VERSION "HIPBNYYYYYYYYYYYYYYYYYYYYYYYYYYYYYYYYYYYYY/4/%%%/4/'%**4YYY///"

NS_ :

BS_:

BU_: DBG VCU BMS MCM DCU DAQ S2C

BO_ 2023 Reserved1: 8 Vector__XXX

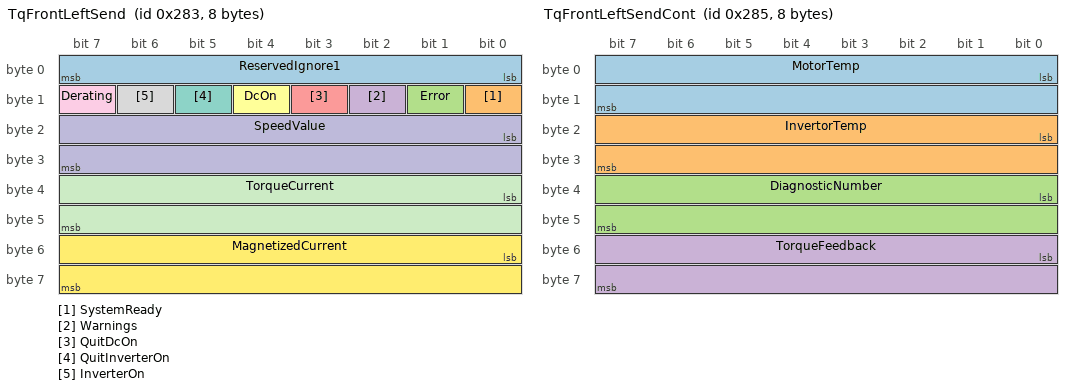
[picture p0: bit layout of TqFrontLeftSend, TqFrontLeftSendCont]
BO_ 643 TqFrontLeftSend: 8 Vector__XXX
 SG_ ReservedIgnore1 : 0|8@1+ (1,0) [0|1] "StatusWord" Vector__XXX
 SG_ SystemReady : 8|1@1+ (1,0) [0|1] "SystemReadySBM" Vector__XXX
 SG_ Error : 9|1@1+ (1,0) [0|1] "" Vector__XXX
 SG_ Warnings : 10|1@1+ (1,0) [0|1] "" Vector__XXX
 SG_ QuitDcOn : 11|1@1+ (1,0) [0|1] "HVActivation" Vector__XXX
 SG_ DcOn : 12|1@1+ (1,0) [0|1] "HVActivationLevel" Vector__XXX
 SG_ QuitInverterOn : 13|1@1+ (1,0) [0|1] "ControllerEnable" Vector__XXX
 SG_ InverterOn : 14|1@1+ (1,0) [0|1] "ControllerEnableAcknow" Vector__XXX
 SG_ Derating : 15|1@1+ (1,0) [0|1] "Nm" Vector__XXX
 SG_ SpeedValue : 16|16@1- (0.01,0) [0|5000] "1/rpm" Vector__XXX
 SG_ TorqueCurrent : 32|16@1- (0.01,0) [0|5000] "Iq" Vector__XXX
 SG_ MagnetizedCurrent : 48|16@1- (0.01,0) [0|5000] "Id" Vector__XXX

BO_ 645 TqFrontLeftSendCont: 8 Vector__XXX
 SG_ MotorTemp : 0|16@1- (0.1,0) [0|500] "C" Vector__XXX
 SG_ InvertorTemp : 16|16@1- (0.1,0) [0|500] "C" Vector__XXX
 SG_ DiagnosticNumber : 32|16@1+ (1,0) [0|20] "" Vector__XXX
 SG_ TorqueFeedback : 48|16@1- (0.1,0) [-30|30] "Nm" Vector__XXX

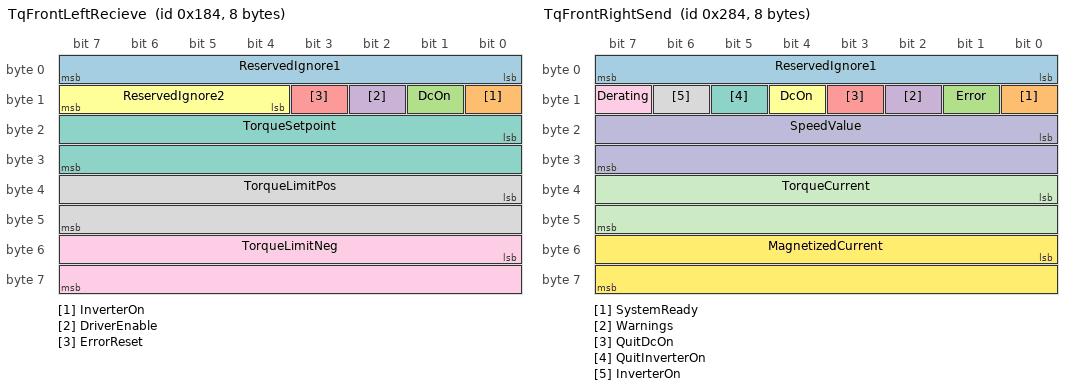
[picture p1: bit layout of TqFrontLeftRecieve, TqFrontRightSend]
BO_ 388 TqFrontLeftRecieve: 8 Vector__XXX
 SG_ ReservedIgnore1 : 0|8@1+ (1,0) [0|1] "" Vector__XXX
 SG_ InverterOn : 8|1@1+ (1,0) [0|1] "" Vector__XXX
 SG_ DcOn : 9|1@1+ (1,0) [0|1] "" Vector__XXX
 SG_ DriverEnable : 10|1@1+ (1,0) [0|1] "" Vector__XXX
 SG_ ErrorReset : 11|1@1+ (1,0) [0|1] "" Vector__XXX
 SG_ ReservedIgnore2 : 12|4@1+ (1,0) [0|1] "" Vector__XXX
 SG_ TorqueSetpoint : 16|16@1- (0.01,0) [-2.14|2.14] "%Nm" Vector__XXX
 SG_ TorqueLimitPos : 32|16@1- (0.1,0) [0|21] "Nm" Vector__XXX
 SG_ TorqueLimitNeg : 48|16@1- (0.1,0) [-21|0] "Nm" Vector__XXX

BO_ 644 TqFrontRightSend: 8 Vector__XXX
 SG_ ReservedIgnore1 : 0|8@1+ (1,0) [0|1] "StatusWord" Vector__XXX
 SG_ SystemReady : 8|1@1+ (1,0) [0|1] "SystemReadySBM" Vector__XXX
 SG_ Error : 9|1@1+ (1,0) [0|1] "" Vector__XXX
 SG_ Warnings : 10|1@1+ (1,0) [0|1] "" Vector__XXX
 SG_ QuitDcOn : 11|1@1+ (1,0) [0|1] "HVActivation" Vector__XXX
 SG_ DcOn : 12|1@1+ (1,0) [0|1] "HVActivationLevel" Vector__XXX
 SG_ QuitInverterOn : 13|1@1+ (1,0) [0|1] "ControllerEnable" Vector__XXX
 SG_ InverterOn : 14|1@1+ (1,0) [0|1] "ControllerEnableAcknow" Vector__XXX
 SG_ Derating : 15|1@1+ (1,0) [0|1] "Nm" Vector__XXX
 SG_ SpeedValue : 16|16@1- (0.01,0) [0|5000] "1/rpm" Vector__XXX
 SG_ TorqueCurrent : 32|16@1- (0.01,0) [0|5000] "Iq" Vector__XXX
 SG_ MagnetizedCurrent : 48|16@1- (0.01,0) [0|5000] "Id" Vector__XXX

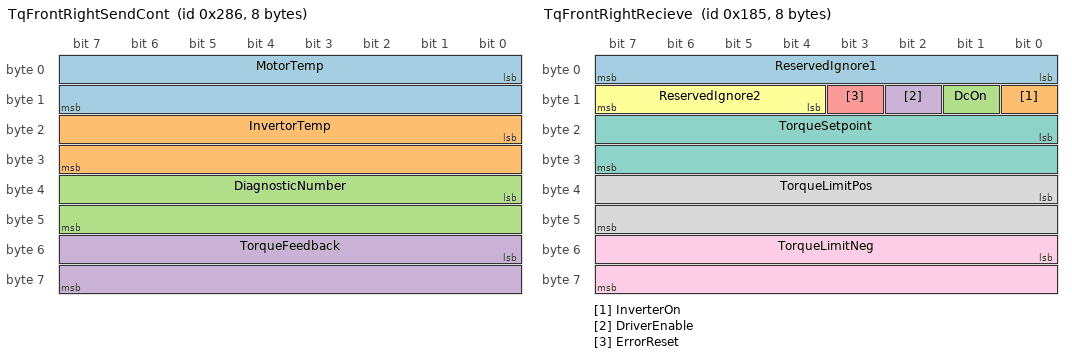
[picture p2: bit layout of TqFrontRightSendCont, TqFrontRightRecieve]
BO_ 646 TqFrontRightSendCont: 8 Vector__XXX
 SG_ MotorTemp : 0|16@1- (0.1,0) [0|500] "C" Vector__XXX
 SG_ InvertorTemp : 16|16@1- (0.1,0) [0|500] "C" Vector__XXX
 SG_ DiagnosticNumber : 32|16@1+ (1,0) [0|20] "" Vector__XXX
 SG_ TorqueFeedback : 48|16@1- (0.1,0) [-30|30] "Nm" Vector__XXX

BO_ 389 TqFrontRightRecieve: 8 Vector__XXX
 SG_ ReservedIgnore1 : 0|8@1+ (1,0) [0|1] "" Vector__XXX
 SG_ InverterOn : 8|1@1+ (1,0) [0|1] "" Vector__XXX
 SG_ DcOn : 9|1@1+ (1,0) [0|1] "" Vector__XXX
 SG_ DriverEnable : 10|1@1+ (1,0) [0|1] "" Vector__XXX
 SG_ ErrorReset : 11|1@1+ (1,0) [0|1] "" Vector__XXX
 SG_ ReservedIgnore2 : 12|4@1+ (1,0) [0|1] "" Vector__XXX
 SG_ TorqueSetpoint : 16|16@1- (0.01,0) [-2.14|2.14] "%Nm" Vector__XXX
 SG_ TorqueLimitPos : 32|16@1- (0.1,0) [0|21] "Nm" Vector__XXX
 SG_ TorqueLimitNeg : 48|16@1- (0.1,0) [-21|0] "Nm" Vector__XXX

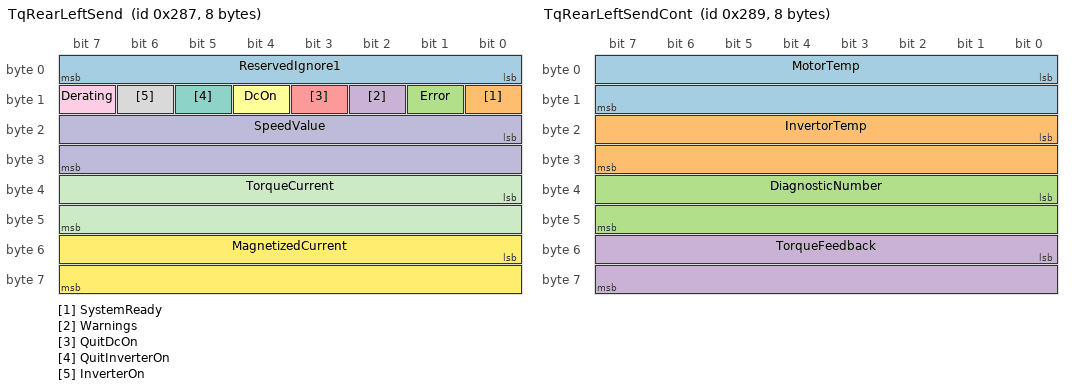
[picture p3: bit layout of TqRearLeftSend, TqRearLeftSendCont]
BO_ 647 TqRearLeftSend: 8 Vector__XXX
 SG_ ReservedIgnore1 : 0|8@1+ (1,0) [0|1] "StatusWord" Vector__XXX
 SG_ SystemReady : 8|1@1+ (1,0) [0|1] "SystemReadySBM" Vector__XXX
 SG_ Error : 9|1@1+ (1,0) [0|1] "" Vector__XXX
 SG_ Warnings : 10|1@1+ (1,0) [0|1] "" Vector__XXX
 SG_ QuitDcOn : 11|1@1+ (1,0) [0|1] "HVActivation" Vector__XXX
 SG_ DcOn : 12|1@1+ (1,0) [0|1] "HVActivationLevel" Vector__XXX
 SG_ QuitInverterOn : 13|1@1+ (1,0) [0|1] "ControllerEnable" Vector__XXX
 SG_ InverterOn : 14|1@1+ (1,0) [0|1] "ControllerEnableAcknow" Vector__XXX
 SG_ Derating : 15|1@1+ (1,0) [0|1] "Nm" Vector__XXX
 SG_ SpeedValue : 16|16@1- (0.01,0) [0|5000] "1/rpm" Vector__XXX
 SG_ TorqueCurrent : 32|16@1- (0.01,0) [0|5000] "Iq" Vector__XXX
 SG_ MagnetizedCurrent : 48|16@1- (0.01,0) [0|5000] "Id" Vector__XXX

BO_ 649 TqRearLeftSendCont: 8 Vector__XXX
 SG_ MotorTemp : 0|16@1- (0.1,0) [0|500] "C" Vector__XXX
 SG_ InvertorTemp : 16|16@1- (0.1,0) [0|500] "C" Vector__XXX
 SG_ DiagnosticNumber : 32|16@1+ (1,0) [0|20] "" Vector__XXX
 SG_ TorqueFeedback : 48|16@1- (0.1,0) [-30|30] "Nm" Vector__XXX

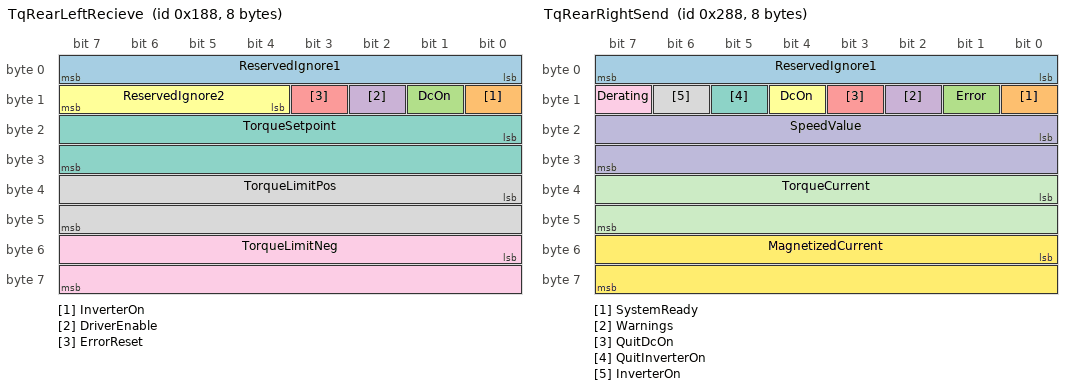
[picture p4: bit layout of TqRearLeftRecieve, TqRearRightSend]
BO_ 392 TqRearLeftRecieve: 8 Vector__XXX
 SG_ ReservedIgnore1 : 0|8@1+ (1,0) [0|1] "" Vector__XXX
 SG_ InverterOn : 8|1@1+ (1,0) [0|1] "" Vector__XXX
 SG_ DcOn : 9|1@1+ (1,0) [0|1] "" Vector__XXX
 SG_ DriverEnable : 10|1@1+ (1,0) [0|1] "" Vector__XXX
 SG_ ErrorReset : 11|1@1+ (1,0) [0|1] "" Vector__XXX
 SG_ ReservedIgnore2 : 12|4@1+ (1,0) [0|1] "" Vector__XXX
 SG_ TorqueSetpoint : 16|16@1- (0.01,0) [-2.14|2.14] "%Nm" Vector__XXX
 SG_ TorqueLimitPos : 32|16@1- (0.1,0) [0|21] "Nm" Vector__XXX
 SG_ TorqueLimitNeg : 48|16@1- (0.1,0) [-21|0] "Nm" Vector__XXX

BO_ 648 TqRearRightSend: 8 Vector__XXX
 SG_ ReservedIgnore1 : 0|8@1+ (1,0) [0|1] "StatusWord" Vector__XXX
 SG_ SystemReady : 8|1@1+ (1,0) [0|1] "SystemReadySBM" Vector__XXX
 SG_ Error : 9|1@1+ (1,0) [0|1] "" Vector__XXX
 SG_ Warnings : 10|1@1+ (1,0) [0|1] "" Vector__XXX
 SG_ QuitDcOn : 11|1@1+ (1,0) [0|1] "HVActivation" Vector__XXX
 SG_ DcOn : 12|1@1+ (1,0) [0|1] "HVActivationLevel" Vector__XXX
 SG_ QuitInverterOn : 13|1@1+ (1,0) [0|1] "ControllerEnable" Vector__XXX
 SG_ InverterOn : 14|1@1+ (1,0) [0|1] "ControllerEnableAcknow" Vector__XXX
 SG_ Derating : 15|1@1+ (1,0) [0|1] "Nm" Vector__XXX
 SG_ SpeedValue : 16|16@1- (0.01,0) [0|5000] "1/rpm" Vector__XXX
 SG_ TorqueCurrent : 32|16@1- (0.01,0) [0|5000] "Iq" Vector__XXX
 SG_ MagnetizedCurrent : 48|16@1- (0.01,0) [0|5000] "Id" Vector__XXX

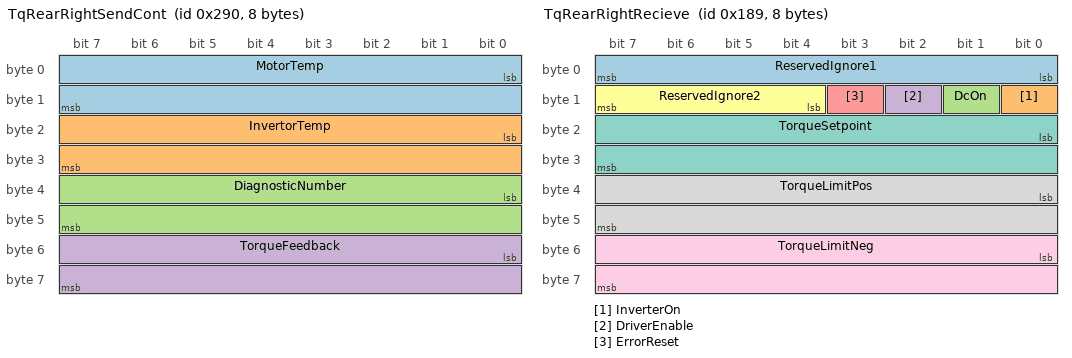
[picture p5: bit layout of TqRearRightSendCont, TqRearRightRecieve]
BO_ 656 TqRearRightSendCont: 8 Vector__XXX
 SG_ MotorTemp : 0|16@1- (0.1,0) [0|500] "C" Vector__XXX
 SG_ InvertorTemp : 16|16@1- (0.1,0) [0|500] "C" Vector__XXX
 SG_ DiagnosticNumber : 32|16@1+ (1,0) [0|20] "" Vector__XXX
 SG_ TorqueFeedback : 48|16@1- (0.1,0) [-30|30] "Nm" Vector__XXX

BO_ 393 TqRearRightRecieve: 8 Vector__XXX
 SG_ ReservedIgnore1 : 0|8@1+ (1,0) [0|1] "" Vector__XXX
 SG_ InverterOn : 8|1@1+ (1,0) [0|1] "" Vector__XXX
 SG_ DcOn : 9|1@1+ (1,0) [0|1] "" Vector__XXX
 SG_ DriverEnable : 10|1@1+ (1,0) [0|1] "" Vector__XXX
 SG_ ErrorReset : 11|1@1+ (1,0) [0|1] "" Vector__XXX
 SG_ ReservedIgnore2 : 12|4@1+ (1,0) [0|1] "" Vector__XXX
 SG_ TorqueSetpoint : 16|16@1- (0.01,0) [-2.14|2.14] "%Nm" Vector__XXX
 SG_ TorqueLimitPos : 32|16@1- (0.1,0) [0|21] "Nm" Vector__XXX
 SG_ TorqueLimitNeg : 48|16@1- (0.1,0) [-21|0] "Nm" Vector__XXX

BO_ 1291 AMK_VCU_Debug: 8 mcm
 SG_ Inverter1_StartUpStage : 0|8@1+ (1,0) [0|10] "" VCU
 SG_ Inverter2_StartUpStage : 8|8@1+ (1,0) [0|10] "" VCU
